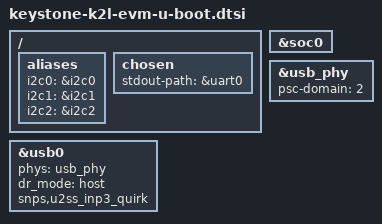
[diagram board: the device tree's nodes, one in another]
// SPDX-License-Identifier: GPL-2.0+
/*
 * Copyright (C) 2019 Texas Instruments Incorporated - https://www.ti.com/
 */

/{
	aliases {
		i2c0 = &i2c0;
		i2c1 = &i2c1;
		i2c2 = &i2c2;
	};

	chosen {
		stdout-path = &uart0;
	};
};

&soc0 {
	bootph-all;
};

&usb_phy {
	#phy-cells = <0>;
	psc-domain = <2>;
};

&usb0 {
	phys = <&usb_phy>;
	dr_mode = "host";
	snps,u2ss_inp3_quirk;
	status = "okay";
};
